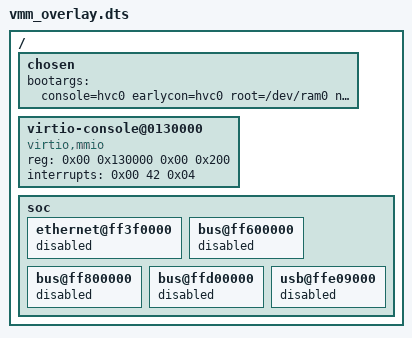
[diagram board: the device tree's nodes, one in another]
// this overlay contains strickly necessary entries (still a lot!) for a passthrough serial to work
// and the virtio net interfaces

/ {

	chosen {
        // bootargs = "console=ttyAML0,115200n8 root=/dev/ram0 nosmp rw debug loglevel=8 pci=nomsi earlyprintk=serial maxcpus=1 ip=172.16.0.11";
        bootargs = "console=hvc0 earlycon=hvc0 root=/dev/ram0 nosmp rw debug loglevel=8 pci=nomsi earlyprintk=serial maxcpus=1";
	};

	// virtio_net@0130000 {
	// 	compatible = "virtio,mmio";
	// 	reg = <0x00 0x130000 0x00 0x200>;
	// 	interrupts = <0x00 42 0x04>;
	// };

	virtio-console@0130000 {
		compatible = "virtio,mmio";
		reg = <0x00 0x130000 0x00 0x200>;
		interrupts = <0x00 42 0x04>;
	};
	
	soc {
		/delete-node/ ethernet@ff3f0000;
		/delete-node/ bus@ff600000;
		/delete-node/ bus@ff800000;
		/delete-node/ bus@ffd00000;
		/delete-node/ usb@ffe09000;

		ethernet@ff3f0000 {
            status = "disabled";
        };

		bus@ff600000 {
            status = "disabled";
        };

		bus@ff800000 {
            status = "disabled";
		};

		bus@ffd00000 {
            status = "disabled";
        };

		usb@ffe09000 {
            status = "disabled";
        };
    };
};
